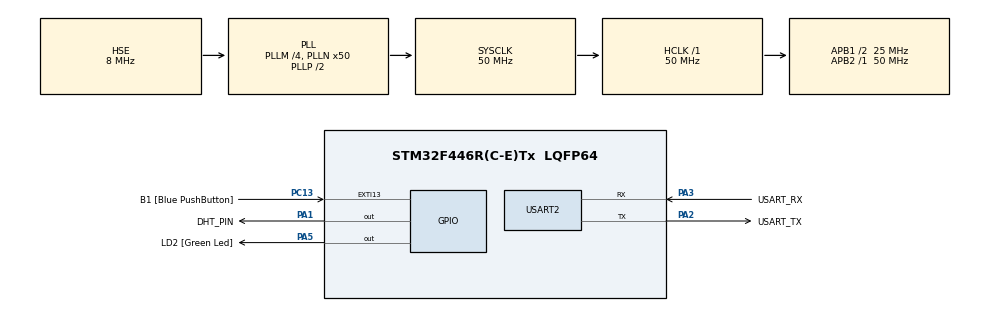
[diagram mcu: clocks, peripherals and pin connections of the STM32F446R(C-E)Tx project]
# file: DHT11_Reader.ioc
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Mcu.Family=STM32F4
Mcu.Name=STM32F446R(C-E)Tx
Mcu.Package=LQFP64
NVIC.PriorityGroup=NVIC_PRIORITYGROUP_0
PA1.GPIO_Label=DHT_PIN
PA1.GPIO_PuPd=GPIO_NOPULL
PA1.Signal=GPIO_Output
PA13.GPIO_Label=TMS
PA13.Mode=Serial_Wire
PA13.Signal=SYS_JTMS-SWDIO
PA14.GPIO_Label=TCK
PA14.Mode=Serial_Wire
PA14.Signal=SYS_JTCK-SWCLK
PA2.GPIO_Label=USART_TX
PA2.Mode=Asynchronous
PA2.Signal=USART2_TX
PA3.GPIO_Label=USART_RX
PA3.Mode=Asynchronous
PA3.Signal=USART2_RX
PA5.GPIO_Label=LD2 [Green Led]
PA5.Signal=GPIO_Output
PB3.GPIO_Label=SWO
PB3.Signal=SYS_JTDO-SWO
PC13.GPIO_Label=B1 [Blue PushButton]
PC13.GPIO_ModeDefaultEXTI=GPIO_MODE_IT_FALLING
PC13.Signal=GPXTI13
PC14-OSC32_IN.Mode=LSE-External-Oscillator
PC14-OSC32_IN.Signal=RCC_OSC32_IN
PC15-OSC32_OUT.Mode=LSE-External-Oscillator
PC15-OSC32_OUT.Signal=RCC_OSC32_OUT
PH0-OSC_IN.Mode=HSE-External-Oscillator
PH0-OSC_IN.Signal=RCC_OSC_IN
PH1-OSC_OUT.Mode=HSE-External-Oscillator
PH1-OSC_OUT.Signal=RCC_OSC_OUT
ProjectManager.HeapSize=0x200
ProjectManager.StackSize=0x400
ProjectManager.TargetToolchain=STM32CubeIDE
RCC.48MHZClocksFreq_Value=84000000
RCC.AHBFreq_Value=50000000
RCC.APB1CLKDivider=RCC_HCLK_DIV2
RCC.APB1Freq_Value=25000000
RCC.APB1TimFreq_Value=50000000
RCC.APB2Freq_Value=50000000
RCC.APB2TimFreq_Value=50000000
RCC.CortexFreq_Value=50000000
RCC.FLatency-AdvancedSettings=FLASH_LATENCY_1
RCC.HCLKFreq_Value=50000000
RCC.HSE_VALUE=8000000
RCC.HSI_VALUE=16000000
RCC.PLLM=4
RCC.PLLN=50
RCC.PLLSourceVirtual=RCC_PLLSOURCE_HSE
RCC.SYSCLKFreq_VALUE=50000000
RCC.SYSCLKSource=RCC_SYSCLKSOURCE_PLLCLK
RCC.USBFreq_Value=50000000
RCC.VCOOutputFreq_Value=100000000
TIM6.Prescaler=50-1
USART2.VirtualMode=VM_ASYNC
VP_TIM6_VS_ClockSourceINT.Mode=Enable_Timer
board=NUCLEO-F446RE

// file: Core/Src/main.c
/* USER CODE BEGIN Header */
/**
 ******************************************************************************
 * @file           : main.c
 * @brief          : Main program body for DHT11 interfacing on STM32
 * @Description	: Main program for DHT11 sensor reading and UART output.
 * This program reads temperature and humidity from a DHT11 sensor connected
 * to STM32 using GPIO and microsecond delays via DWT. The data is printed
 *	over UART (e.g., USART2).
 *
 *	@author         : Nitin R
 * @date           : May 21, 2025
 ******************************************************************************
 * COPYRIGHT(c) 2025 STMicroelectronics
 *
 * Redistribution and use in source and binary forms, with or without modification,
 * are permitted under ST's license terms...
 ******************************************************************************
 */
/* USER CODE END Header */

#include "main.h"
#include "stm32f4xx.h"
#include "stdio.h"
#include "stdint.h"
#include "string.h"
#include <stdlib.h>  /* for atoi() */

#include "dht11.h"
#include "my_debug.h"

/* USER CODE BEGIN PM */
#define DHT_PIN_Pin GPIO_PIN_1
#define DHT_PIN_GPIO_Port GPIOA

/* #define DEBUG_PRINT(...) printf(__VA_ARGS__) */

/* USER CODE END PM */

TIM_HandleTypeDef htim6;
UART_HandleTypeDef huart2;

void SystemClock_Config(void);
static void MX_GPIO_Init(void);
static void MX_USART2_UART_Init(void);
static void MX_TIM6_Init(void);

/* USER CODE BEGIN 0 */

/** Retarget printf to USART2 ------------------------------------------------
 * The first block is a common way to make printf retargeting work on multiple compilers by defining the appropriate function. */

#ifdef __GNUC__
#define PUTCHAR_PROTOTYPE int __io_putchar(int ch)
#else
#define PUTCHAR_PROTOTYPE int fputc(int ch, FILE *f)
#endif

PUTCHAR_PROTOTYPE {
	HAL_UART_Transmit(&huart2, (uint8_t*) &ch, 1, 0xFFFF);
	return (ch);
}

/** Retarget printf to USART2 ------------------------------------------------
 If you only target GCC and want simplicity, second block works fine.

 int __io_putchar(int ch) {
 HAL_UART_Transmit(&huart2, (uint8_t *)&ch, 1, HAL_MAX_DELAY);
 return ch;
 }*/

int main(void) {
	/* Initialize the HAL Library */
	HAL_Init();

	/* Configure the system clock */
	SystemClock_Config();

	/* Initialize all configured peripherals */
	MX_GPIO_Init();
	MX_USART2_UART_Init();
	MX_TIM6_Init();
	HAL_TIM_Base_Start(&htim6); /* Start TIM6 for any timing operations (optional) */
	DWT_Init(); /* Enable DWT-based microsecond delay*/
	printf("*******Welcome to the DHT11_Reader *********\r\n");
	HAL_Delay(1000); /* Give DHT11 time to stabilize */

	/* Infinite loop to read DHT11 sensor
	 * Main loop: Continuously read temperature and humidity from DHT11 sensor
	 * and display the values over UART every 2 seconds.*/
	while (1) {
		ReadAndDisplayDHT11();
	}
}

void SystemClock_Config(void) {
	RCC_OscInitTypeDef RCC_OscInitStruct = { 0 };
	RCC_ClkInitTypeDef RCC_ClkInitStruct = { 0 };

	/** Configure the main internal regulator output voltage
	 */
	__HAL_RCC_PWR_CLK_ENABLE();
	__HAL_PWR_VOLTAGESCALING_CONFIG(PWR_REGULATOR_VOLTAGE_SCALE3);

	/** Initializes the RCC Oscillators according to the specified parameters
	 * in the RCC_OscInitTypeDef structure.
	 */
	RCC_OscInitStruct.OscillatorType = RCC_OSCILLATORTYPE_HSE;
	RCC_OscInitStruct.HSEState = RCC_HSE_ON;
	RCC_OscInitStruct.PLL.PLLState = RCC_PLL_ON;
	RCC_OscInitStruct.PLL.PLLSource = RCC_PLLSOURCE_HSE;
	RCC_OscInitStruct.PLL.PLLM = 4;
	RCC_OscInitStruct.PLL.PLLN = 50;
	RCC_OscInitStruct.PLL.PLLP = RCC_PLLP_DIV2;
	RCC_OscInitStruct.PLL.PLLQ = 2;
	RCC_OscInitStruct.PLL.PLLR = 2;
	if (HAL_RCC_OscConfig(&RCC_OscInitStruct) != HAL_OK) {
		Error_Handler();
	}

	/** Initializes the CPU, AHB and APB buses clocks
	 */
	RCC_ClkInitStruct.ClockType = RCC_CLOCKTYPE_HCLK | RCC_CLOCKTYPE_SYSCLK
			| RCC_CLOCKTYPE_PCLK1 | RCC_CLOCKTYPE_PCLK2;
	RCC_ClkInitStruct.SYSCLKSource = RCC_SYSCLKSOURCE_PLLCLK;
	RCC_ClkInitStruct.AHBCLKDivider = RCC_SYSCLK_DIV1;
	RCC_ClkInitStruct.APB1CLKDivider = RCC_HCLK_DIV2;
	RCC_ClkInitStruct.APB2CLKDivider = RCC_HCLK_DIV1;

	if (HAL_RCC_ClockConfig(&RCC_ClkInitStruct, FLASH_LATENCY_1) != HAL_OK) {
		Error_Handler();
	}
}

static void MX_TIM6_Init(void) {

	TIM_MasterConfigTypeDef sMasterConfig = { 0 };

	htim6.Instance = TIM6;
	htim6.Init.Prescaler = 84 - 1;
	htim6.Init.CounterMode = TIM_COUNTERMODE_UP;
	htim6.Init.Period = 0xFFFF - 1;
	htim6.Init.AutoReloadPreload = TIM_AUTORELOAD_PRELOAD_DISABLE;
	if (HAL_TIM_Base_Init(&htim6) != HAL_OK) {
		Error_Handler();
	}
	sMasterConfig.MasterOutputTrigger = TIM_TRGO_RESET;
	sMasterConfig.MasterSlaveMode = TIM_MASTERSLAVEMODE_DISABLE;
	if (HAL_TIMEx_MasterConfigSynchronization(&htim6, &sMasterConfig)
			!= HAL_OK) {
		Error_Handler();
	}

}

static void MX_USART2_UART_Init(void) {

	huart2.Instance = USART2;
	huart2.Init.BaudRate = 115200;
	huart2.Init.WordLength = UART_WORDLENGTH_8B;
	huart2.Init.StopBits = UART_STOPBITS_1;
	huart2.Init.Parity = UART_PARITY_NONE;
	huart2.Init.Mode = UART_MODE_TX_RX;
	huart2.Init.HwFlowCtl = UART_HWCONTROL_NONE;
	huart2.Init.OverSampling = UART_OVERSAMPLING_16;
	if (HAL_UART_Init(&huart2) != HAL_OK) {
		Error_Handler();
	}

}

static void MX_GPIO_Init(void) {
	GPIO_InitTypeDef GPIO_InitStruct = { 0 };

	/* GPIO Ports Clock Enable */
	__HAL_RCC_GPIOC_CLK_ENABLE();
	__HAL_RCC_GPIOH_CLK_ENABLE();
	__HAL_RCC_GPIOA_CLK_ENABLE();
	__HAL_RCC_GPIOB_CLK_ENABLE();

	/*Configure GPIO pin Output Level */
	HAL_GPIO_WritePin(GPIOA, LD2_Pin, GPIO_PIN_RESET);

	/*Configure GPIO pin : B1_Pin */
	GPIO_InitStruct.Pin = B1_Pin;
	GPIO_InitStruct.Mode = GPIO_MODE_INPUT;
	GPIO_InitStruct.Pull = GPIO_NOPULL;
	HAL_GPIO_Init(B1_GPIO_Port, &GPIO_InitStruct);

	/*Configure GPIO pins :  LD2_Pin */
	GPIO_InitStruct.Pin = LD2_Pin;
	GPIO_InitStruct.Mode = GPIO_MODE_OUTPUT_PP;
	GPIO_InitStruct.Pull = GPIO_PULLUP;
	GPIO_InitStruct.Speed = GPIO_SPEED_FREQ_LOW;
	HAL_GPIO_Init(GPIOA, &GPIO_InitStruct);

	/*Configure GPIO pins : DHT_PIN_Pin Pin */
	/*	GPIO_InitStruct.Pin = DHT_PIN_Pin;
	 GPIO_InitStruct.Mode = GPIO_MODE_OUTPUT_PP;
	 GPIO_InitStruct.Pull = GPIO_NOPULL;
	 GPIO_InitStruct.Speed = GPIO_SPEED_FREQ_LOW;
	 HAL_GPIO_Init(GPIOA, &GPIO_InitStruct);

	 / USER CODE BEGIN MX_GPIO_Init_2 */
	/* USER CODE END MX_GPIO_Init_2 */

}

void Error_Handler(void) {
	__disable_irq();
	while (1) {
	}
}
